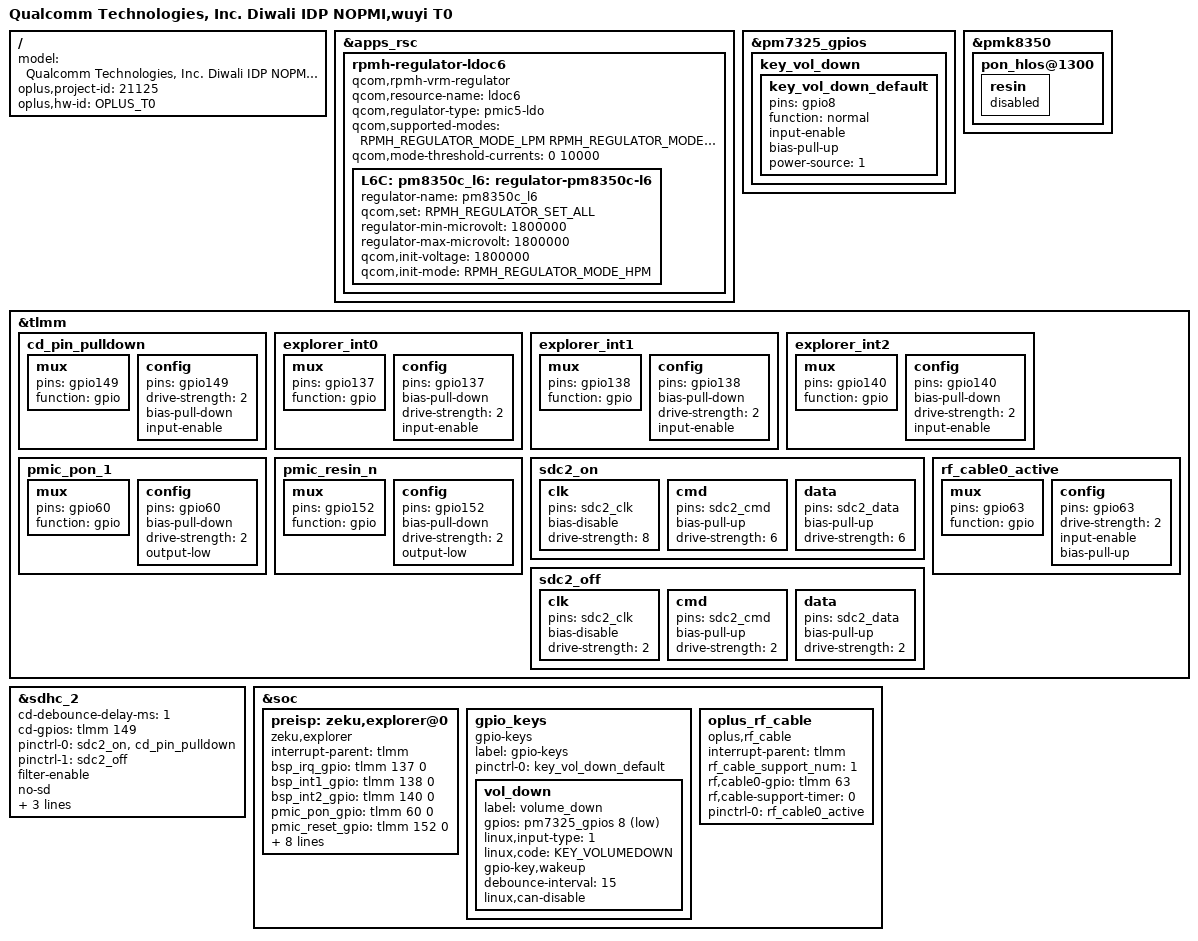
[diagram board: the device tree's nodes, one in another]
/dts-v1/;
/plugin/;
#include <dt-bindings/oplus/hw-id.h>
#include "../qcom/diwali-idp-nopmi-overlay.dts"
#include "diwail_overlay_common.dtsi"
#include "sensor/wuyi-sensor-21125.dtsi"
#include "wuyi_overlay_common.dtsi"
#include "oplus_chg/oplus-chg-21125.dtsi"
#include "oplus_uff/oplus_uff_21125.dtsi"
#include "nfc/wuyi-nfc-sn110t.dtsi"
#include <dt-bindings/regulator/qcom,rpmh-regulator-levels.h>
#include <dt-bindings/clock/qcom,rpmh.h>
/ {
    model = "Qualcomm Technologies, Inc. Diwali IDP NOPMI,wuyi T0";

    oplus,project-id = <21125>;
    oplus,hw-id = <OPLUS_T0>;
};

&apps_rsc {
	rpmh-regulator-ldoc6 {
		compatible = "qcom,rpmh-vrm-regulator";
		qcom,resource-name = "ldoc6";
		qcom,regulator-type = "pmic5-ldo";
		qcom,supported-modes =
			<RPMH_REGULATOR_MODE_LPM
			 RPMH_REGULATOR_MODE_HPM>;
		qcom,mode-threshold-currents = <0 10000>;
		L6C: pm8350c_l6: regulator-pm8350c-l6 {
			regulator-name = "pm8350c_l6";
			qcom,set = <RPMH_REGULATOR_SET_ALL>;
			regulator-min-microvolt = <1800000>;
			regulator-max-microvolt = <1800000>;
			qcom,init-voltage = <1800000>;
			qcom,init-mode = <RPMH_REGULATOR_MODE_HPM>;
		};
	};
};

/*#ifdef OPLUS_FEATURE_TP_BASIC*/
&pm7325_gpios {
	key_vol_down {
		key_vol_down_default: key_vol_down_default {
			pins = "gpio8";
			function = "normal";
			input-enable;
			bias-pull-up;
			power-source = <1>;
		};
	};
};

&pmk8350 {
	pon_hlos@1300 {
		resin {
		    status = "disabled";
		};
	};
};
/*#endif OPLUS_FEATURE_TP_BASIC*/

&tlmm {
	cd_pin_pulldown: cd_pin_pulldown {
		mux {
			pins = "gpio149";
			function = "gpio";
		};
		config {
			pins = "gpio149";
			drive-strength = <2>;
			bias-pull-down;
			input-enable;
		};
	};

	explorer_int0: explorer_int0 {
		mux {
			pins = "gpio137";
			function = "gpio";
		};
		config {
			pins = "gpio137";
			bias-pull-down;
			drive-strength = <2>;
			input-enable;
		};
	};

	explorer_int1: explorer_int1 {
		mux {
			pins = "gpio138";
			function = "gpio";
		};
		config {
			pins = "gpio138";
			bias-pull-down;
			drive-strength = <2>;
			input-enable;
		};
	};

	explorer_int2: explorer_int2 {
		mux {
			pins = "gpio140";
			function = "gpio";
		};
		config {
			pins = "gpio140";
			bias-pull-down;
			drive-strength = <2>;
			input-enable;
		};
	};

	pmic_pon_1: pmic_pon_1 {
		mux {
			pins = "gpio60";
			function = "gpio";
		};
		config {
			pins = "gpio60";
			bias-pull-down;
			drive-strength = <2>;
			output-low;
		};
	};

	pmic_resin_n: pmic_resin_n {
		mux {
			pins = "gpio152";
			function = "gpio";
		};
		config {
			pins = "gpio152";
			bias-pull-down;
			drive-strength = <2>;
			output-low;
		};
	};

	sdc2_on: sdc2_on {
		clk {
			pins = "sdc2_clk";
			bias-disable;
			drive-strength = <8>;
		};
		cmd {
			pins = "sdc2_cmd";
			bias-pull-up;
			drive-strength = <6>;
		};
		data {
			pins = "sdc2_data";
			bias-pull-up;
			drive-strength = <6>;
		};
	};

	sdc2_off: sdc2_off {
		clk {
			pins = "sdc2_clk";
			bias-disable;
			drive-strength = <2>;
		};
		cmd {
			pins = "sdc2_cmd";
			bias-pull-up;
			drive-strength = <2>;
		};
		data {
			pins = "sdc2_data";
			bias-pull-up;
			drive-strength = <2>;
		};
	};
};

&sdhc_2 {
	cd-debounce-delay-ms = <1>;
	cd-gpios = <&tlmm 149 GPIO_ACTIVE_HIGH>;
	pinctrl-names = "default", "sleep";
	pinctrl-0 = <&sdc2_on &cd_pin_pulldown>;
	pinctrl-1 = <&sdc2_off>;
	filter-enable;
	no-sd;
	no-mmc;
	qcom,vdd-io-voltage-level = <1800000 1800000>;
	qcom,vdd-voltage-level = <3300000 3300000>;
	status = "ok";
};

&soc {
	preisp: zeku,explorer@0 {
		compatible = "zeku,explorer";
		interrupt-parent = <&tlmm>;
		bsp_irq_gpio = <&tlmm 137 0>;
		bsp_int1_gpio = <&tlmm 138 0>;
		bsp_int2_gpio = <&tlmm 140 0>;
		pmic_pon_gpio = <&tlmm 60 0>;
		pmic_reset_gpio = <&tlmm 152 0>;
		ignore-dsleep;
		pinctrl-names = "default";
		pinctrl-0 = <&explorer_int0 &explorer_int1 &explorer_int2 &pmic_pon_1 &pmic_resin_n>;
		clock-names = "clk_ref";
		clocks = <&rpmhcc RPMH_RF_CLK5>;
		vcc_sdio-supply = <&L6C>;
		explorer,clk-drive-strength = <4>;
		explorer,cmd-drive-strength = <4>;
		explorer,data-drive-strength = <4>;
	};
        /*#ifdef OPLUS_FEATURE_TP_BASIC*/
        gpio_keys {
		compatible = "gpio-keys";
		label = "gpio-keys";

		pinctrl-names = "default";
		pinctrl-0 = <&key_vol_down_default>;

		vol_down {
			label = "volume_down";
			gpios = <&pm7325_gpios 8 GPIO_ACTIVE_LOW>;
			linux,input-type = <1>;
			linux,code = <KEY_VOLUMEDOWN>;
			gpio-key,wakeup;
			debounce-interval = <15>;
			linux,can-disable;
		};
	};
        /*#endif OPLUS_FEATURE_TP_BASIC*/
};

//#ifdef OPLUS_FEATURE_RF_CABLE_DETECT
&tlmm {
  rf_cable0_active: rf_cable0_active {
    mux {
      pins = "gpio63";
      function = "gpio";
    };
    config {
      pins = "gpio63";
      drive-strength = <2>;
      input-enable;
      bias-pull-up;
    };
  };
};

&soc {
  oplus_rf_cable {
    compatible = "oplus,rf_cable";
    interrupt-parent = <&tlmm>;
    rf_cable_support_num = <1>;
    rf,cable0-gpio = <&tlmm 63 0>;
    rf,cable-support-timer = <0>;
    pinctrl-names = "rf_cable_active";
    pinctrl-0 = <&rf_cable0_active>;
  };
};
 //#endif /* OPLUS_FEATURE_RF_CABLE_DETECT */
